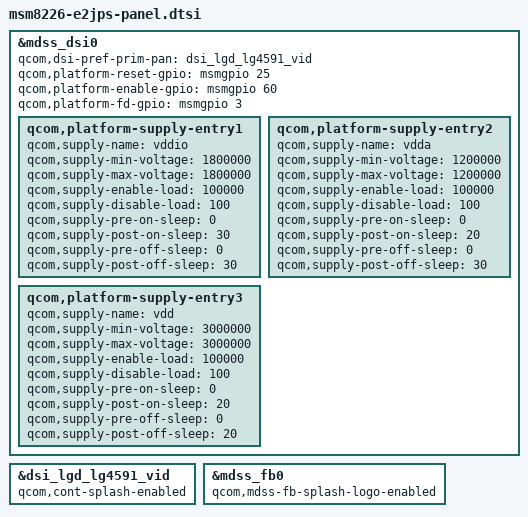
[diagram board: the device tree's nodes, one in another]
/* Copyright (c) 2013, Code Aurora Forum. All rights reserved.
 *
 * This program is free software; you can redistribute it and/or modify
 * it under the terms of the GNU General Public License version 2 and
 * only version 2 as published by the Free Software Foundation.
 *
 * This program is distributed in the hope that it will be useful,
 * but WITHOUT ANY WARRANTY; without even the implied warranty of
 * MERCHANTABILITY or FITNESS FOR A PARTICULAR PURPOSE.  See the
 * GNU General Public License for more details.
 */

&mdss_dsi0 {
	qcom,dsi-pref-prim-pan = <&dsi_lgd_lg4591_vid>;
	qcom,platform-reset-gpio = <&msmgpio 25 0>;
	qcom,platform-enable-gpio = <&msmgpio 60 0>;
	qcom,platform-fd-gpio = <&msmgpio 3 0>;
	qcom,platform-supply-entry1 {
		qcom,supply-name = "vddio";
		qcom,supply-min-voltage = <1800000>;
		qcom,supply-max-voltage = <1800000>;
		qcom,supply-enable-load = <100000>;
		qcom,supply-disable-load = <100>;
		qcom,supply-pre-on-sleep = <0>;
		qcom,supply-post-on-sleep = <30>;
		qcom,supply-pre-off-sleep = <0>;
		qcom,supply-post-off-sleep = <30>;
	};
	qcom,platform-supply-entry2 {
	    qcom,supply-name = "vdda";
	    qcom,supply-min-voltage = <1200000>;
	    qcom,supply-max-voltage = <1200000>;
	    qcom,supply-enable-load = <100000>;
	    qcom,supply-disable-load = <100>;
	    qcom,supply-pre-on-sleep = <0>;
	    qcom,supply-post-on-sleep = <20>;
	    qcom,supply-pre-off-sleep = <0>;
	    qcom,supply-post-off-sleep = <30>;
	};
	qcom,platform-supply-entry3 {
		qcom,supply-name = "vdd";
		qcom,supply-min-voltage = <3000000>;
		qcom,supply-max-voltage = <3000000>;
		qcom,supply-enable-load = <100000>;
		qcom,supply-disable-load = <100>;
		qcom,supply-pre-on-sleep = <0>;
		qcom,supply-post-on-sleep = <20>;
		qcom,supply-pre-off-sleep = <0>;
		qcom,supply-post-off-sleep = <20>;
	};
};

&dsi_lgd_lg4591_vid {
	qcom,cont-splash-enabled;
	status = "ok";
};

&mdss_fb0 {
	qcom,mdss-fb-splash-logo-enabled;
};
